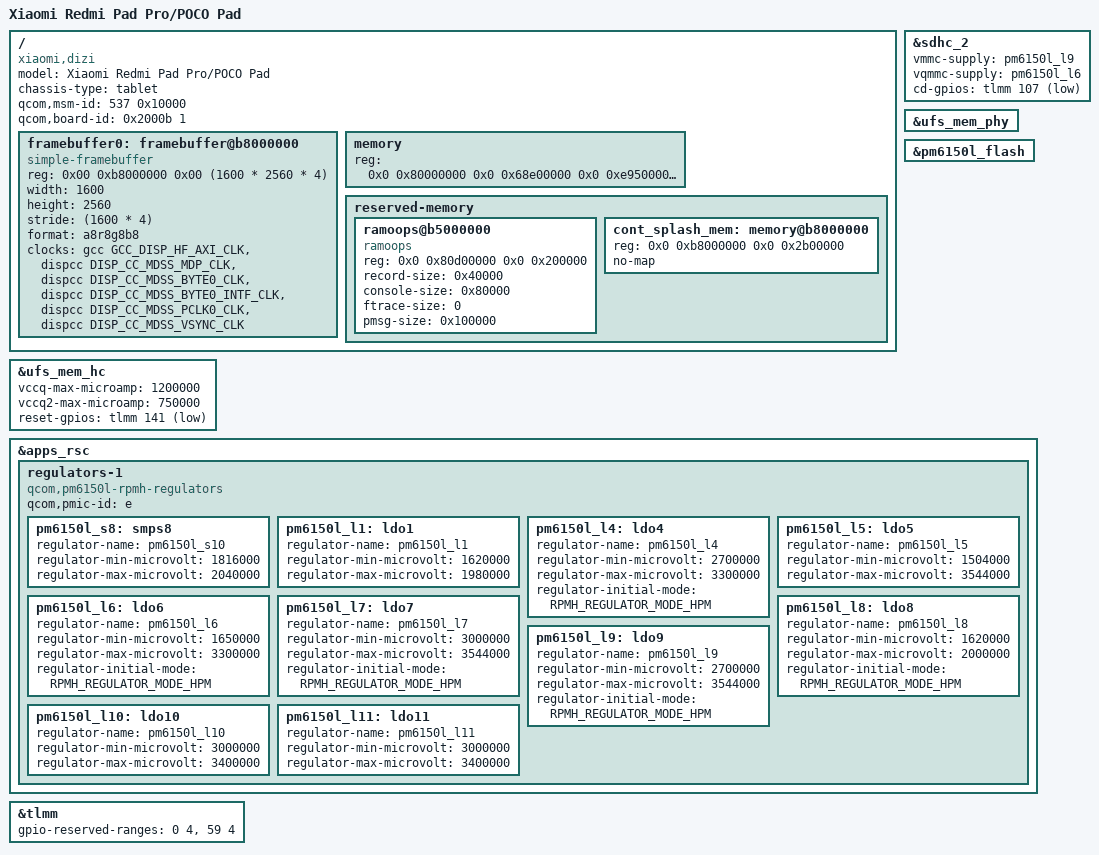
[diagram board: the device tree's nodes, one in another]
// SPDX-License-Identifier: BSD-3-Clause
/*
 * Copyright (c) 2025 Artur Weber <aweber.kernel@gmail.com>
 */

/dts-v1/;

#include <dt-bindings/regulator/qcom,rpmh-regulator.h>

#include "netrani.dtsi"
#include "pmk8350.dtsi"
#include "pm6450.dtsi"
#include "pm6150l.dtsi"

/ {
	model = "Xiaomi Redmi Pad Pro/POCO Pad";
	compatible = "xiaomi,dizi", "qcom,sm7435", "qcom,netrani";
	chassis-type = "tablet";

	qcom,msm-id = <537 0x10000>; // TODO: are the other values needed?
	qcom,board-id = <0x2000b 1>;

	framebuffer0: framebuffer@b8000000 {
		compatible = "simple-framebuffer";
		reg = <0x00 0xb8000000 0x00 (1600 * 2560 * 4)>;
		width = <1600>;
		height = <2560>;
		stride = <(1600 * 4)>;
		format = "a8r8g8b8";

		clocks = <&gcc GCC_DISP_HF_AXI_CLK>,
				<&dispcc DISP_CC_MDSS_MDP_CLK>,
				<&dispcc DISP_CC_MDSS_BYTE0_CLK>,
				<&dispcc DISP_CC_MDSS_BYTE0_INTF_CLK>,
				<&dispcc DISP_CC_MDSS_PCLK0_CLK>,
				<&dispcc DISP_CC_MDSS_VSYNC_CLK>;
		//power-domains = <&dispcc DISP_CC_MDSS_CORE_GDSC>;
	};

	memory {
		device_type = "memory";
		reg = <0x0 0x80000000 0x0 0x68e00000 0x0 0xe9500000 0x0 0x0 0x0 0xea700000 0x0 0x15900000 0x8 0x0 0x0 0x3fd00000 0x8 0x40000000 0x0 0x7ab00000 0x8 0xc0000000 0x0 0x40000000 0x8 0xbb100000 0x0 0x1e00000>;
	};

	reserved-memory {
		ramoops@b5000000 {
			compatible = "ramoops";
			reg = <0x0 0x80d00000 0x0 0x200000>;
			record-size = <0x40000>;
			console-size = <0x80000>;
			ftrace-size = <0>;
			pmsg-size = <0x100000>;
		};

		cont_splash_mem: memory@b8000000 {
			reg = <0x0 0xb8000000 0x0 0x2b00000>;
			no-map;
		};
	};
};

&sdhc_2 {
	vmmc-supply = <&pm6150l_l9>;
	vqmmc-supply = <&pm6150l_l6>;

	cd-gpios = <&tlmm 107 GPIO_ACTIVE_LOW>;
	status = "okay";
};

&ufs_mem_hc {
	//vcc-supply = <&pm6450_l24>;
	//vccq-supply = <&pm6450_l13>;
	//vdd-hba-supply = <&gdsc>;
	//vccq2-supply = <&pm6450_l19>;
	vccq-max-microamp = <1200000>;
	vccq2-max-microamp = <750000>;

	reset-gpios = <&tlmm 141 GPIO_ACTIVE_LOW>;

	status = "okay";
};

&ufs_mem_phy {
	//vdda-phy-supply = <&pm6450_l5>;
	//vdda-pll-supply = <&pm6450_l16>;
	status = "okay";
};

&pm6150l_flash {
	status = "okay";

	// TODO: LED subnodes
};

/*
 * Other PMICs:
 * - pmr735a@6, unused
 * - pm7250b@8 and @9, unused (vibrator node is on, but device has no vibrator)
 */

&apps_rsc {
	/*regulators-0 {
		compatible = "qcom,pm6450-rpmh-regulators";
		qcom,pmic-id = "b";

		pm6450_s6: smps6 {
			regulator-name = "pm6450_s6";
			regulator-min-microvolt = <1010000>;
			regulator-max-microvolt = <1170000>;
		};

		pm6450_s7: smps7 {
			regulator-name = "pm6450_s7";
			regulator-min-microvolt = <880000>;
			regulator-max-microvolt = <1174000>;
		};

		pm6450_s8: smps8 {
			regulator-name = "pm6450_s8";
			regulator-min-microvolt = <1224000>;
			regulator-max-microvolt = <1654000>;
		};

		pm6450_s9: smps9 {
			regulator-name = "pm6450_s9";
			regulator-min-microvolt = <850000>;
			regulator-max-microvolt = <2208000>;
		};

		pm6450_l1: ldo1 {
			regulator-name = "pm6450_l1";
			regulator-min-microvolt = <300000>;
			regulator-max-microvolt = <650000>;
			regulator-initial-mode = <RPMH_REGULATOR_MODE_HPM>;
		};

		pm6450_l3: ldo3 {
			regulator-name = "pm6450_l3";
			regulator-min-microvolt = <870000>;
			regulator-max-microvolt = <970000>;
			regulator-initial-mode = <RPMH_REGULATOR_MODE_HPM>;
		};

		pm6450_l4: ldo4 {
			regulator-name = "pm6450_l4";
			regulator-min-microvolt = <530000>;
			regulator-max-microvolt = <864000>;
			regulator-initial-mode = <RPMH_REGULATOR_MODE_HPM>;
		};

		pm6450_l5: ldo5 {
			regulator-name = "pm6450_l5";
			regulator-min-microvolt = <830000>;
			regulator-max-microvolt = <920000>;
			regulator-initial-mode = <RPMH_REGULATOR_MODE_HPM>;
		};

		pm6450_l6: ldo6 {
			regulator-name = "pm6450_l6";
			regulator-min-microvolt = <751000>;
			regulator-max-microvolt = <824000>;
			regulator-initial-mode = <RPMH_REGULATOR_MODE_HPM>;
		};

		pm6450_l7: ldo7 {
			regulator-name = "pm6450_l7";
			regulator-min-microvolt = <830000>;
			regulator-max-microvolt = <920000>;
			regulator-initial-mode = <RPMH_REGULATOR_MODE_HPM>;
		};

		pm6450_l8: ldo8 {
			regulator-name = "pm6450_l8";
			regulator-min-microvolt = <870000>;
			regulator-max-microvolt = <970000>;
			regulator-initial-mode = <RPMH_REGULATOR_MODE_HPM>;
		};

		pm6450_l10: ldo10 {
			regulator-name = "pm6450_l10";
			regulator-min-microvolt = <824000>;
			regulator-max-microvolt = <950000>;
			regulator-initial-mode = <RPMH_REGULATOR_MODE_HPM>;
		};

		pm6450_l11: ldo11 {
			regulator-name = "pm6450_l11";
			regulator-min-microvolt = <348000>;
			regulator-max-microvolt = <888000>;
		};

		pm6450_l12: ldo12 {
			regulator-name = "pm6450_l12";
			regulator-min-microvolt = <1080000>;
			regulator-max-microvolt = <1240000>;
			regulator-initial-mode = <RPMH_REGULATOR_MODE_HPM>;
		};

		pm6450_l13: ldo13 {
			regulator-name = "pm6450_l13";
			regulator-min-microvolt = <1080000>;
			regulator-max-microvolt = <1304000>;
			regulator-initial-mode = <RPMH_REGULATOR_MODE_HPM>;
		};

		pm6450_l14: ldo14 {
			regulator-name = "pm6450_l14";
			regulator-min-microvolt = <1150000>;
			regulator-max-microvolt = <1304000>;
			regulator-initial-mode = <RPMH_REGULATOR_MODE_HPM>;
		};

		pm6450_l15: ldo15 {
			regulator-name = "pm6450_l15";
			regulator-min-microvolt = <1080000>;
			regulator-max-microvolt = <1304000>;
			regulator-initial-mode = <RPMH_REGULATOR_MODE_HPM>;
		};

		pm6450_l16: ldo16 {
			regulator-name = "pm6450_l16";
			regulator-min-microvolt = <1140000>;
			regulator-max-microvolt = <1260000>;
			regulator-initial-mode = <RPMH_REGULATOR_MODE_HPM>;
		};

		pm6450_l17: ldo17 {
			regulator-name = "pm6450_l17";
			regulator-min-microvolt = <1200000>;
			regulator-max-microvolt = <1200000>;
			regulator-initial-mode = <RPMH_REGULATOR_MODE_HPM>;
		};

		pm6450_l18: ldo18 {
			regulator-name = "pm6450_l18";
			regulator-min-microvolt = <1504000>;
			regulator-max-microvolt = <2000000>;
			regulator-initial-mode = <RPMH_REGULATOR_MODE_HPM>;
		};

		pm6450_l19: ldo19 {
			regulator-name = "pm6450_l19";
			regulator-min-microvolt = <1620000>;
			regulator-max-microvolt = <1980000>;
			regulator-initial-mode = <RPMH_REGULATOR_MODE_HPM>;
		};

		pm6450_l20: ldo20 {
			regulator-name = "pm6450_l20";
			regulator-min-microvolt = <1700000>;
			regulator-max-microvolt = <1900000>;
			regulator-initial-mode = <RPMH_REGULATOR_MODE_HPM>;
		};

		pm6450_l21: ldo21 {
			regulator-name = "pm6450_l21";
			regulator-min-microvolt = <1800000>;
			regulator-max-microvolt = <1950000>;
			regulator-initial-mode = <RPMH_REGULATOR_MODE_HPM>;
		};

		pm6450_l22: ldo22 {
			regulator-name = "pm6450_l22";
			regulator-min-microvolt = <1800000>;
			regulator-max-microvolt = <2000000>;
			regulator-initial-mode = <RPMH_REGULATOR_MODE_HPM>;
		};

		pm6450_l23: ldo23 {
			regulator-name = "pm6450_l23";
			regulator-min-microvolt = <1650000>;
			regulator-max-microvolt = <1950000>;
			regulator-initial-mode = <RPMH_REGULATOR_MODE_HPM>;
		};

		// TODO: l24 does not have min/max values???

		pm6450_l25: ldo25 {
			regulator-name = "pm6450_l25";
			regulator-min-microvolt = <2700000>;
			regulator-max-microvolt = <3544000>;
			regulator-initial-mode = <RPMH_REGULATOR_MODE_HPM>;
		};

		pm6450_l26: ldo26 {
			regulator-name = "pm6450_l26";
			regulator-min-microvolt = <1620000>;
			regulator-max-microvolt = <3300000>;
			regulator-initial-mode = <RPMH_REGULATOR_MODE_HPM>;
		};

		pm6450_l27: ldo27 {
			regulator-name = "pm6450_l27";
			regulator-min-microvolt = <1620000>;
			regulator-max-microvolt = <3300000>;
			regulator-initial-mode = <RPMH_REGULATOR_MODE_HPM>;
		};

		pm6450_l28: ldo28 {
			regulator-name = "pm6450_l28";
			regulator-min-microvolt = <2700000>;
			regulator-max-microvolt = <3544000>;
			regulator-initial-mode = <RPMH_REGULATOR_MODE_HPM>;
		};
	};*/

	regulators-1 {
		compatible = "qcom,pm6150l-rpmh-regulators";
		qcom,pmic-id = "e";

		pm6150l_s8: smps8 {
			regulator-name = "pm6150l_s10";
			regulator-min-microvolt = <1816000>;
			regulator-max-microvolt = <2040000>;
		};

		pm6150l_l1: ldo1 {
			regulator-name = "pm6150l_l1";
			regulator-min-microvolt = <1620000>;
			regulator-max-microvolt = <1980000>;
		};

		pm6150l_l4: ldo4 {
			regulator-name = "pm6150l_l4";
			regulator-min-microvolt = <2700000>;
			regulator-max-microvolt = <3300000>;
			regulator-initial-mode = <RPMH_REGULATOR_MODE_HPM>;
		};

		pm6150l_l5: ldo5 {
			regulator-name = "pm6150l_l5";
			regulator-min-microvolt = <1504000>;
			regulator-max-microvolt = <3544000>;
		};

		pm6150l_l6: ldo6 {
			regulator-name = "pm6150l_l6";
			regulator-min-microvolt = <1650000>;
			regulator-max-microvolt = <3300000>;
			regulator-initial-mode = <RPMH_REGULATOR_MODE_HPM>;
		};

		pm6150l_l7: ldo7 {
			regulator-name = "pm6150l_l7";
			regulator-min-microvolt = <3000000>;
			regulator-max-microvolt = <3544000>;
			regulator-initial-mode = <RPMH_REGULATOR_MODE_HPM>;
		};

		pm6150l_l8: ldo8 {
			regulator-name = "pm6150l_l8";
			regulator-min-microvolt = <1620000>;
			regulator-max-microvolt = <2000000>;
			regulator-initial-mode = <RPMH_REGULATOR_MODE_HPM>;
		};

		pm6150l_l9: ldo9 {
			regulator-name = "pm6150l_l9";
			regulator-min-microvolt = <2700000>;
			regulator-max-microvolt = <3544000>;
			regulator-initial-mode = <RPMH_REGULATOR_MODE_HPM>;
		};

		pm6150l_l10: ldo10 {
			regulator-name = "pm6150l_l10";
			regulator-min-microvolt = <3000000>;
			regulator-max-microvolt = <3400000>;
		};

		pm6150l_l11: ldo11 {
			regulator-name = "pm6150l_l11";
			regulator-min-microvolt = <3000000>;
			regulator-max-microvolt = <3400000>;
		};
	};
};

&tlmm {
	gpio-reserved-ranges = <0 4>, <59 4>;
};
